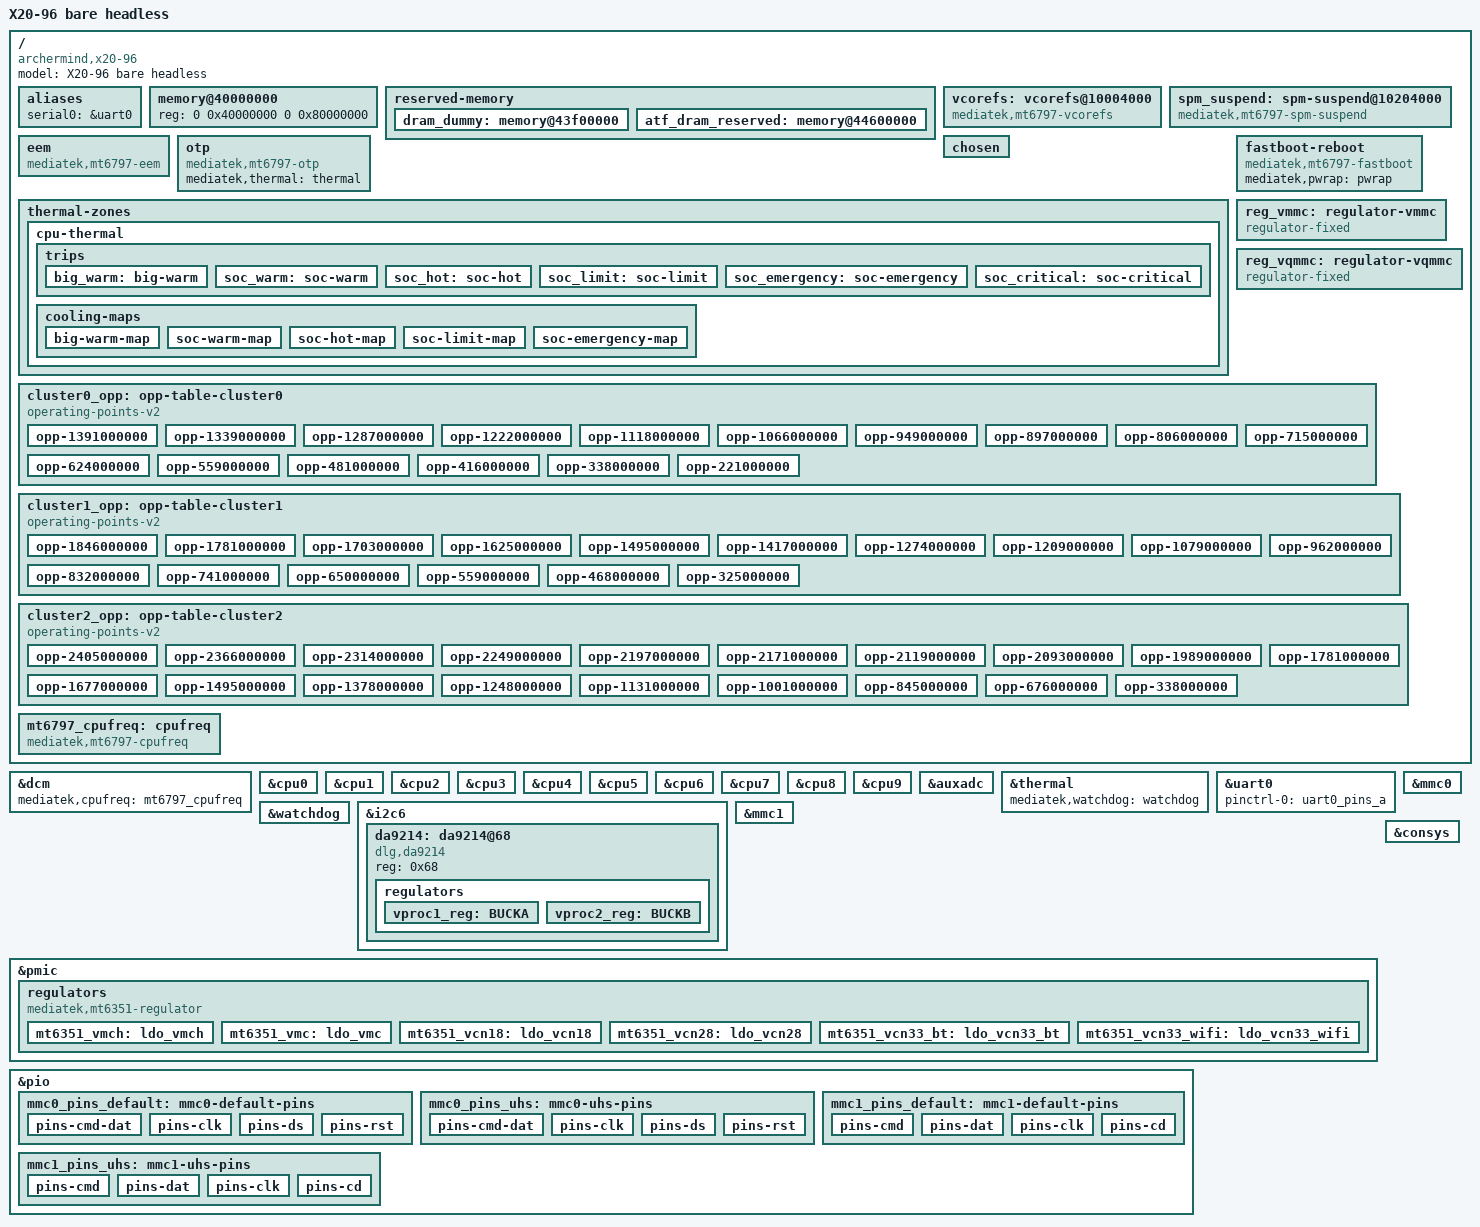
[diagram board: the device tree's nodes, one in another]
// SPDX-License-Identifier: GPL-2.0-only
/*
 * Device Tree for the bare X20-96 board.
 *
 * This is intentionally the first, headless bring-up description.  The board
 * has no display or expansion board attached, so only the serial console is
 * enabled until each onboard peripheral is verified separately.
 */

/dts-v1/;

#include <dt-bindings/pinctrl/mt65xx.h>
#include <dt-bindings/gpio/gpio.h>
#include <dt-bindings/regulator/dlg,da9211-regulator.h>
#include <dt-bindings/thermal/thermal.h>
#include "mt6797-x20-96-cooling.h"
#include "mt6797.dtsi"

&dcm {
	mediatek,cpufreq = <&mt6797_cpufreq>;
	status = "okay";
};

/ {
	model = "X20-96 bare headless";
	compatible = "archermind,x20-96", "mediatek,mt6797";

	aliases {
		serial0 = &uart0;
	};

	memory@40000000 {
		device_type = "memory";
		reg = <0 0x40000000 0 0x80000000>;
	};

	reserved-memory {
		#address-cells = <2>;
		#size-cells = <2>;
		ranges;

		/* Dedicated dummy reads for the board's single DRAM rank. */
		dram_dummy: memory@43f00000 {
			reg = <0 0x43f00000 0 0x1000>;
			no-map;
		};

		/* The BSP Preloader locks this former BL31 DRAM window in EMI MPU. */
		atf_dram_reserved: memory@44600000 {
			reg = <0 0x44600000 0 0x10000>;
			no-map;
		};
	};

	vcorefs: vcorefs@10004000 {
		compatible = "mediatek,mt6797-vcorefs";
		reg = <0 0x10004000 0 0x1000>,
		      <0 0x1000f000 0 0x1000>,
		      <0 0x1000d10c 0 0x80>,
		      <0 0x08000008 0 4>,
		      <0 0x11015000 0 0x1000>,
		      <0 0x11016000 0 0x1000>;
		reg-names = "dramc", "ddrphy", "pwrap-dvfs", "chip-version",
			    "cpu-spm", "big-spm";
		mediatek,infracfg = <&infrasys>;
		mediatek,spm = <&scpsys>;
		mediatek,pmic-wrapper = <&pwrap>;
		mediatek,dcm = <&dcm>;
		clocks = <&topckgen CLK_TOP_MUX_SPM>,
			 <&infrasys CLK_INFRA_DVFS_SPM1>,
			 <&topckgen CLK_TOP_MUX_DDRPHYCFG>,
			 <&infrasys CLK_INFRA_DRAMC_CONF>,
			 <&infrasys CLK_INFRA_DRAMC_B_CONF>,
			 <&topckgen CLK_TOP_MUX_AXI>,
			 <&topckgen CLK_TOP_SYSPLL_D7>,
			 <&topckgen CLK_TOP_MUX_ULPOSC_AXI_CK_MUX>;
		clock-names = "spm", "dvfs", "ddrphy", "dramc", "dramc-b",
			      "axi", "axi-high", "axi-low";
		memory-region = <&dram_dummy>;
	};

	spm_suspend: spm-suspend@10204000 {
		compatible = "mediatek,mt6797-spm-suspend";
		reg = <0 0x10204000 0 0x1000>;
		clocks = <&infrasys CLK_INFRA_SYS_CIRQ>;
		clock-names = "cirq";
		mediatek,vcorefs = <&vcorefs>;
		mediatek,watchdog = <&watchdog>;
		mediatek,gic = <&gic>;
		mediatek,sysirq = <&sysirq>;
		interrupt-parent = <&sysirq>;
		interrupts = <GIC_SPI 180 IRQ_TYPE_LEVEL_LOW>;
		wakeup-source;
	};

	eem {
		compatible = "mediatek,mt6797-eem";
		mediatek,thermal = <&thermal>;
		mediatek,cpufreq = <&mt6797_cpufreq>;
		nvmem-cells = <&eem_calibration>;
		nvmem-cell-names = "calibration-data";
	};

	otp {
		compatible = "mediatek,mt6797-otp";
		mediatek,thermal = <&thermal>;
	};

	chosen {
		stdout-path = "serial0:921600n8";
		/* Loader overrides this for initramfs rescue; fallback is eMMC. */
		bootargs = "console=ttyS0,921600n8 root=PARTUUID=8273e1ab-846f-4468-b999-ee2ea8e50a16 rootwait printk.time=1";
	};

	thermal-zones {
		cpu-thermal {
			polling-delay-passive = <100>;
			polling-delay = <100>;
			thermal-sensors = <&thermal>;

			trips {
				big_warm: big-warm {
					temperature = <120000>;
					hysteresis = <5000>;
					type = "passive";
				};

				soc_warm: soc-warm {
					temperature = <135000>;
					hysteresis = <10000>;
					type = "passive";
				};

				soc_hot: soc-hot {
					temperature = <140000>;
					hysteresis = <10000>;
					type = "passive";
				};

				soc_limit: soc-limit {
					temperature = <143000>;
					hysteresis = <13000>;
					type = "passive";
				};

				soc_emergency: soc-emergency {
					temperature = <145000>;
					hysteresis = <15000>;
					type = "passive";
				};

				soc_critical: soc-critical {
					temperature = <150000>;
					hysteresis = <2000>;
					type = "critical";
				};
			};

			cooling-maps {
				big-warm-map {
					trip = <&big_warm>;
					cooling-device = <&cpu8 X20_BIG_STATE_2314000
							 X20_BIG_STATE_2314000>;
				};

				soc-warm-map {
					trip = <&soc_warm>;
					cooling-device = <&cpu8 X20_BIG_STATE_1677000
							 X20_BIG_STATE_1677000>,
							 <&cpu0 X20_LL_STATE_1066000
							 X20_LL_STATE_1066000>,
							 <&cpu4 X20_L_STATE_1209000
							 X20_L_STATE_1209000>;
				};

				soc-hot-map {
					trip = <&soc_hot>;
					cooling-device = <&cpu8 X20_BIG_STATE_1495000
							 X20_BIG_STATE_1495000>,
							 <&cpu0 X20_LL_STATE_806000
							 X20_LL_STATE_806000>,
							 <&cpu4 X20_L_STATE_832000
							 X20_L_STATE_832000>;
				};

				soc-limit-map {
					trip = <&soc_limit>;
					cooling-device = <&cpu8 X20_BIG_STATE_1001000
							 X20_BIG_STATE_1001000>,
							 <&cpu0 X20_LL_STATE_559000
							 X20_LL_STATE_559000>,
							 <&cpu4 X20_L_STATE_650000
							 X20_L_STATE_650000>;
				};

				soc-emergency-map {
					trip = <&soc_emergency>;
					cooling-device = <&cpu8 X20_BIG_STATE_338000
							 X20_BIG_STATE_338000>,
							 <&cpu0 X20_LL_STATE_221000
							 X20_LL_STATE_221000>,
							 <&cpu4 X20_L_STATE_325000
							 X20_L_STATE_325000>;
				};
			};
		};
	};

	fastboot-reboot {
		compatible = "mediatek,mt6797-fastboot";
		mediatek,pwrap = <&pwrap>;
	};

	reg_vmmc: regulator-vmmc {
		compatible = "regulator-fixed";
		regulator-name = "vmmc-3v3";
		regulator-min-microvolt = <3300000>;
		regulator-max-microvolt = <3300000>;
		regulator-always-on;
		regulator-boot-on;
	};

	reg_vqmmc: regulator-vqmmc {
		compatible = "regulator-fixed";
		regulator-name = "vqmmc-1v8";
		regulator-min-microvolt = <1800000>;
		regulator-max-microvolt = <1800000>;
		regulator-always-on;
		regulator-boot-on;
	};

	/* FY operating points copied from the vendor MT6797 tables. */
	cluster0_opp: opp-table-cluster0 {
		compatible = "operating-points-v2";
		opp-shared;
		clock-latency-ns = <30000>;

		opp-1391000000 { opp-hz = /bits/ 64 <1391000000>; opp-microvolt = <1180000>; };
		opp-1339000000 { opp-hz = /bits/ 64 <1339000000>; opp-microvolt = <1160000>; };
		opp-1287000000 { opp-hz = /bits/ 64 <1287000000>; opp-microvolt = <1130000>; };
		opp-1222000000 { opp-hz = /bits/ 64 <1222000000>; opp-microvolt = <1110000>; };
		opp-1118000000 { opp-hz = /bits/ 64 <1118000000>; opp-microvolt = <1090000>; };
		opp-1066000000 { opp-hz = /bits/ 64 <1066000000>; opp-microvolt = <1070000>; };
		opp-949000000 { opp-hz = /bits/ 64 <949000000>; opp-microvolt = <1020000>; };
		opp-897000000 { opp-hz = /bits/ 64 <897000000>; opp-microvolt = <1000000>; };
		opp-806000000 { opp-hz = /bits/ 64 <806000000>; opp-microvolt = <970000>; };
		opp-715000000 { opp-hz = /bits/ 64 <715000000>; opp-microvolt = <940000>; };
		opp-624000000 { opp-hz = /bits/ 64 <624000000>; opp-microvolt = <900000>; };
		opp-559000000 { opp-hz = /bits/ 64 <559000000>; opp-microvolt = <880000>; };
		opp-481000000 { opp-hz = /bits/ 64 <481000000>; opp-microvolt = <850000>; };
		opp-416000000 { opp-hz = /bits/ 64 <416000000>; opp-microvolt = <830000>; };
		opp-338000000 { opp-hz = /bits/ 64 <338000000>; opp-microvolt = <800000>; };
		opp-221000000 { opp-hz = /bits/ 64 <221000000>; opp-microvolt = <780000>; };
	};

	cluster1_opp: opp-table-cluster1 {
		compatible = "operating-points-v2";
		opp-shared;
		clock-latency-ns = <30000>;

		opp-1846000000 { opp-hz = /bits/ 64 <1846000000>; opp-microvolt = <1180000>; };
		opp-1781000000 { opp-hz = /bits/ 64 <1781000000>; opp-microvolt = <1160000>; };
		opp-1703000000 { opp-hz = /bits/ 64 <1703000000>; opp-microvolt = <1130000>; };
		opp-1625000000 { opp-hz = /bits/ 64 <1625000000>; opp-microvolt = <1110000>; };
		opp-1495000000 { opp-hz = /bits/ 64 <1495000000>; opp-microvolt = <1090000>; };
		opp-1417000000 { opp-hz = /bits/ 64 <1417000000>; opp-microvolt = <1070000>; };
		opp-1274000000 { opp-hz = /bits/ 64 <1274000000>; opp-microvolt = <1020000>; };
		opp-1209000000 { opp-hz = /bits/ 64 <1209000000>; opp-microvolt = <1000000>; };
		opp-1079000000 { opp-hz = /bits/ 64 <1079000000>; opp-microvolt = <970000>; };
		opp-962000000 { opp-hz = /bits/ 64 <962000000>; opp-microvolt = <940000>; };
		opp-832000000 { opp-hz = /bits/ 64 <832000000>; opp-microvolt = <900000>; };
		opp-741000000 { opp-hz = /bits/ 64 <741000000>; opp-microvolt = <880000>; };
		opp-650000000 { opp-hz = /bits/ 64 <650000000>; opp-microvolt = <850000>; };
		opp-559000000 { opp-hz = /bits/ 64 <559000000>; opp-microvolt = <830000>; };
		opp-468000000 { opp-hz = /bits/ 64 <468000000>; opp-microvolt = <800000>; };
		opp-325000000 { opp-hz = /bits/ 64 <325000000>; opp-microvolt = <780000>; };
	};

	cluster2_opp: opp-table-cluster2 {
		compatible = "operating-points-v2";
		opp-shared;
		clock-latency-ns = <30000>;

		/* Board experiment curve; no requests above the verified 2.405 GHz. */
		/* Highest tested execution point, using the user voltage curve. */
		opp-2405000000 { opp-hz = /bits/ 64 <2405000000>; opp-microvolt = <1110000>; };
		opp-2366000000 { opp-hz = /bits/ 64 <2366000000>; opp-microvolt = <1090000>; };
		opp-2314000000 { opp-hz = /bits/ 64 <2314000000>; opp-microvolt = <1070000>; };
		opp-2249000000 { opp-hz = /bits/ 64 <2249000000>; opp-microvolt = <1160000>; };
		opp-2197000000 { opp-hz = /bits/ 64 <2197000000>; opp-microvolt = <1150000>; };
		opp-2171000000 { opp-hz = /bits/ 64 <2171000000>; opp-microvolt = <1140000>; };
		opp-2119000000 { opp-hz = /bits/ 64 <2119000000>; opp-microvolt = <1120000>; };
		opp-2093000000 { opp-hz = /bits/ 64 <2093000000>; opp-microvolt = <1110000>; };
		opp-1989000000 { opp-hz = /bits/ 64 <1989000000>; opp-microvolt = <1100000>; };
		opp-1781000000 { opp-hz = /bits/ 64 <1781000000>; opp-microvolt = <1060000>; };
		opp-1677000000 { opp-hz = /bits/ 64 <1677000000>; opp-microvolt = <1040000>; };
		opp-1495000000 { opp-hz = /bits/ 64 <1495000000>; opp-microvolt = <990000>; };
		opp-1378000000 { opp-hz = /bits/ 64 <1378000000>; opp-microvolt = <970000>; };
		opp-1248000000 { opp-hz = /bits/ 64 <1248000000>; opp-microvolt = <940000>; };
		opp-1131000000 { opp-hz = /bits/ 64 <1131000000>; opp-microvolt = <920000>; };
		opp-1001000000 { opp-hz = /bits/ 64 <1001000000>; opp-microvolt = <890000>; };
		opp-845000000 { opp-hz = /bits/ 64 <845000000>; opp-microvolt = <870000>; };
		opp-676000000 { opp-hz = /bits/ 64 <676000000>; opp-microvolt = <840000>; };
		opp-338000000 { opp-hz = /bits/ 64 <338000000>; opp-microvolt = <800000>; };
	};

	mt6797_cpufreq: cpufreq {
		compatible = "mediatek,mt6797-cpufreq";
		reg = <0 0x1001a000 0 0x1000>,
		      <0 0x10000000 0 0x1000>,
		      <0 0x11015000 0 0x1000>,
		      <0 0x10001000 0 0x1000>;
		reg-names = "mcumixed", "topckgen", "semaphore", "infracfg";
		status = "okay";
	};
};

/* Short on-board Dhrystone gives A53:A72 DMIPS/MHz approximately 2:3.
 * Linux combines these per-MHz weights with each policy maximum.
 */
&cpu0 { operating-points-v2 = <&cluster0_opp>; capacity-dmips-mhz = <667>; cpu-supply = <&vproc1_reg>; };
&cpu1 { operating-points-v2 = <&cluster0_opp>; capacity-dmips-mhz = <667>; cpu-supply = <&vproc1_reg>; };
&cpu2 { operating-points-v2 = <&cluster0_opp>; capacity-dmips-mhz = <667>; cpu-supply = <&vproc1_reg>; };
&cpu3 { operating-points-v2 = <&cluster0_opp>; capacity-dmips-mhz = <667>; cpu-supply = <&vproc1_reg>; };
&cpu4 { operating-points-v2 = <&cluster1_opp>; capacity-dmips-mhz = <667>; cpu-supply = <&vproc1_reg>; };
&cpu5 { operating-points-v2 = <&cluster1_opp>; capacity-dmips-mhz = <667>; cpu-supply = <&vproc1_reg>; };
&cpu6 { operating-points-v2 = <&cluster1_opp>; capacity-dmips-mhz = <667>; cpu-supply = <&vproc1_reg>; };
&cpu7 { operating-points-v2 = <&cluster1_opp>; capacity-dmips-mhz = <667>; cpu-supply = <&vproc1_reg>; };
&cpu8 { operating-points-v2 = <&cluster2_opp>; capacity-dmips-mhz = <1000>; cpu-supply = <&vproc2_reg>; };
&cpu9 { operating-points-v2 = <&cluster2_opp>; capacity-dmips-mhz = <1000>; cpu-supply = <&vproc2_reg>; };

&auxadc {
	status = "okay";
};

&thermal {
	mediatek,watchdog = <&watchdog>;
	status = "okay";
};

&uart0 {
	status = "okay";
	pinctrl-names = "default";
	pinctrl-0 = <&uart0_pins_a>;
};

/* TOPRGU is the board's hardware reset path, including reboot-to-Fastboot. */
&watchdog {
	status = "okay";
};

/* The board carries the vendor-designated DA9214 VPROC buck at I2C6/0x68. */
&i2c6 {
	pinctrl-names = "default";
	pinctrl-0 = <&i2c6_pins_a>;
	clock-frequency = <3400000>;
	mediatek,use-push-pull;
	status = "okay";

	da9214: da9214@68 {
		compatible = "dlg,da9214";
		reg = <0x68>;

		regulators {
			vproc1_reg: BUCKA {
				regulator-name = "vproc1";
				regulator-min-microvolt = <780000>;
				regulator-max-microvolt = <1200000>;
				regulator-initial-mode = <DA9211_BUCK_MODE_SYNC>;
				regulator-allowed-modes = <DA9211_BUCK_MODE_SYNC
						   DA9211_BUCK_MODE_AUTO>;
				regulator-always-on;
			};

			vproc2_reg: BUCKB {
				regulator-name = "vproc2";
				regulator-min-microvolt = <800000>;
				regulator-max-microvolt = <1200000>;
				regulator-initial-mode = <DA9211_BUCK_MODE_SYNC>;
				regulator-allowed-modes = <DA9211_BUCK_MODE_SYNC
						   DA9211_BUCK_MODE_AUTO>;
				regulator-always-on;
			};
		};
	};
};

&mmc0 {
	/* Validated high-throughput descriptor DMA path for HS400. */
	bus-width = <8>;
	max-frequency = <200000000>;
	cap-mmc-highspeed;
	mmc-ddr-1_8v;
	mmc-hs200-1_8v;
	mmc-hs400-1_8v;
	mediatek,latch-ck = <1>;
	mediatek,tuning-step = <64>;
	non-removable;
	no-sd;
	no-sdio;
	vmmc-supply = <&reg_vmmc>;
	vqmmc-supply = <&reg_vqmmc>;
	pinctrl-names = "default", "state_uhs";
	pinctrl-0 = <&mmc0_pins_default>;
	pinctrl-1 = <&mmc0_pins_uhs>;
	status = "okay";
};

&mmc1 {
	/* Validated UHS-I path; the Loader still boots eMMC/MSDC0 only. */
	bus-width = <4>;
	max-frequency = <104000000>;
	cap-sd-highspeed;
	sd-uhs-sdr104;
	/* This X20-96 board reports card insertion high on GPIO67. */
	cd-gpios = <&pio 67 GPIO_ACTIVE_HIGH>;
	vmmc-supply = <&mt6351_vmch>;
	vqmmc-supply = <&mt6351_vmc>;
	pinctrl-names = "default", "state_uhs";
	pinctrl-0 = <&mmc1_pins_default>;
	pinctrl-1 = <&mmc1_pins_uhs>;
	status = "okay";
};

&pmic {
	regulators {
		compatible = "mediatek,mt6351-regulator";

		mt6351_vmch: ldo_vmch {
			regulator-name = "vmch";
			regulator-min-microvolt = <3300000>;
			regulator-max-microvolt = <3300000>;
			regulator-always-on;
			regulator-boot-on;
		};

		mt6351_vmc: ldo_vmc {
			regulator-name = "vmc";
			regulator-min-microvolt = <1800000>;
			/* SD legacy/high-speed signalling starts at 3.3 V. */
			regulator-max-microvolt = <3300000>;
			regulator-boot-on;
		};

		/*
		 * Connectivity rails for the MT6797 ConSys and the MT6631
		 * radio: AVDD18_WBT, TCXO/FM 2.8 V and the separate VCN33
		 * BT/WiFi outputs.  Each rail has a hardware-fixed voltage.
		 */
		mt6351_vcn18: ldo_vcn18 {
			regulator-name = "vcn18";
			regulator-min-microvolt = <1800000>;
			regulator-max-microvolt = <1800000>;
		};

		mt6351_vcn28: ldo_vcn28 {
			regulator-name = "vcn28";
			regulator-min-microvolt = <2800000>;
			regulator-max-microvolt = <2800000>;
		};

		mt6351_vcn33_bt: ldo_vcn33_bt {
			regulator-name = "vcn33_bt";
			regulator-min-microvolt = <3300000>;
			regulator-max-microvolt = <3300000>;
		};

		mt6351_vcn33_wifi: ldo_vcn33_wifi {
			regulator-name = "vcn33_wifi";
			regulator-min-microvolt = <3300000>;
			regulator-max-microvolt = <3300000>;
		};
	};
};

/* Wi-Fi/BT/GPS connectivity subsystem; driver is an opt-in module. */
&consys {
	status = "okay";
};

&pio {
	mmc0_pins_default: mmc0-default-pins {
		pins-cmd-dat {
			pinmux = <MT6797_GPIO114__FUNC_MSDC0_DAT0>,
				 <MT6797_GPIO115__FUNC_MSDC0_DAT1>,
				 <MT6797_GPIO116__FUNC_MSDC0_DAT2>,
				 <MT6797_GPIO117__FUNC_MSDC0_DAT3>,
				 <MT6797_GPIO118__FUNC_MSDC0_DAT4>,
				 <MT6797_GPIO119__FUNC_MSDC0_DAT5>,
				 <MT6797_GPIO120__FUNC_MSDC0_DAT6>,
				 <MT6797_GPIO121__FUNC_MSDC0_DAT7>,
				 <MT6797_GPIO122__FUNC_MSDC0_CMD>;
			input-enable;
			input-schmitt-enable;
			bias-pull-up = <MTK_PUPD_SET_R1R0_01>;
			drive-strength = <4>;
			mediatek,tdsel = <0>;
			mediatek,rdsel = <0>;
		};

		pins-clk {
			pinmux = <MT6797_GPIO123__FUNC_MSDC0_CLK>;
			input-enable;
			input-schmitt-enable;
			bias-pull-down = <MTK_PUPD_SET_R1R0_10>;
			drive-strength = <4>;
			mediatek,tdsel = <0>;
			mediatek,rdsel = <0>;
		};

		pins-ds {
			pinmux = <MT6797_GPIO124__FUNC_MSDC0_DSL>;
			input-enable;
			input-schmitt-enable;
			bias-pull-down = <MTK_PUPD_SET_R1R0_10>;
			drive-strength = <4>;
			mediatek,tdsel = <0>;
			mediatek,rdsel = <0>;
		};

		pins-rst {
			pinmux = <MT6797_GPIO125__FUNC_MSDC0_RSTB>;
			input-enable;
			input-schmitt-enable;
			bias-pull-up = <MTK_PUPD_SET_R1R0_01>;
			drive-strength = <4>;
			mediatek,tdsel = <0>;
			mediatek,rdsel = <0>;
		};
	};

	mmc0_pins_uhs: mmc0-uhs-pins {
		pins-cmd-dat {
			pinmux = <MT6797_GPIO114__FUNC_MSDC0_DAT0>,
				 <MT6797_GPIO115__FUNC_MSDC0_DAT1>,
				 <MT6797_GPIO116__FUNC_MSDC0_DAT2>,
				 <MT6797_GPIO117__FUNC_MSDC0_DAT3>,
				 <MT6797_GPIO118__FUNC_MSDC0_DAT4>,
				 <MT6797_GPIO119__FUNC_MSDC0_DAT5>,
				 <MT6797_GPIO120__FUNC_MSDC0_DAT6>,
				 <MT6797_GPIO121__FUNC_MSDC0_DAT7>,
				 <MT6797_GPIO122__FUNC_MSDC0_CMD>;
			input-enable;
			input-schmitt-enable;
			bias-pull-up = <MTK_PUPD_SET_R1R0_01>;
			drive-strength = <4>;
			mediatek,tdsel = <0>;
			mediatek,rdsel = <0>;
		};

		pins-clk {
			pinmux = <MT6797_GPIO123__FUNC_MSDC0_CLK>;
			input-enable;
			input-schmitt-enable;
			bias-pull-down = <MTK_PUPD_SET_R1R0_10>;
			drive-strength = <4>;
			mediatek,tdsel = <0>;
			mediatek,rdsel = <0>;
		};

		pins-ds {
			pinmux = <MT6797_GPIO124__FUNC_MSDC0_DSL>;
			input-enable;
			input-schmitt-enable;
			bias-pull-down = <MTK_PUPD_SET_R1R0_10>;
			drive-strength = <4>;
			mediatek,tdsel = <0>;
			mediatek,rdsel = <0>;
		};

		pins-rst {
			pinmux = <MT6797_GPIO125__FUNC_MSDC0_RSTB>;
			input-enable;
			input-schmitt-enable;
			bias-pull-up = <MTK_PUPD_SET_R1R0_01>;
			drive-strength = <4>;
			mediatek,tdsel = <0>;
			mediatek,rdsel = <0>;
		};
	};

	mmc1_pins_default: mmc1-default-pins {
		pins-cmd {
			pinmux = <MT6797_GPIO129__FUNC_MSDC1_CMD>;
			input-enable;
			input-schmitt-enable;
			bias-pull-up = <MTK_PUPD_SET_R1R0_10>;
			drive-strength = <4>;
			mediatek,tdsel = <10>;
			mediatek,rdsel = <3>;
		};

		pins-dat {
			pinmux = <MT6797_GPIO130__FUNC_MSDC1_DAT0>,
				 <MT6797_GPIO131__FUNC_MSDC1_DAT1>,
				 <MT6797_GPIO132__FUNC_MSDC1_DAT2>,
				 <MT6797_GPIO133__FUNC_MSDC1_DAT3>;
			input-enable;
			input-schmitt-enable;
			bias-pull-up = <MTK_PUPD_SET_R1R0_10>;
			drive-strength = <4>;
			mediatek,tdsel = <10>;
			mediatek,rdsel = <3>;
		};

		pins-clk {
			pinmux = <MT6797_GPIO134__FUNC_MSDC1_CLK>;
			input-enable;
			input-schmitt-enable;
			bias-pull-down = <MTK_PUPD_SET_R1R0_10>;
			drive-strength = <4>;
			mediatek,tdsel = <10>;
			mediatek,rdsel = <0>;
		};

		pins-cd {
			pinmux = <MT6797_GPIO67__FUNC_GPIO67>;
			input-enable;
			bias-pull-up;
		};
	};

	mmc1_pins_uhs: mmc1-uhs-pins {
		pins-cmd {
			pinmux = <MT6797_GPIO129__FUNC_MSDC1_CMD>;
			input-enable;
			input-schmitt-enable;
			bias-pull-up = <MTK_PUPD_SET_R1R0_10>;
			drive-strength = <4>;
			mediatek,tdsel = <10>;
			mediatek,rdsel = <0>;
		};

		pins-dat {
			pinmux = <MT6797_GPIO130__FUNC_MSDC1_DAT0>,
				 <MT6797_GPIO131__FUNC_MSDC1_DAT1>,
				 <MT6797_GPIO132__FUNC_MSDC1_DAT2>,
				 <MT6797_GPIO133__FUNC_MSDC1_DAT3>;
			input-enable;
			input-schmitt-enable;
			bias-pull-up = <MTK_PUPD_SET_R1R0_10>;
			drive-strength = <4>;
			mediatek,tdsel = <10>;
			mediatek,rdsel = <0>;
		};

		pins-clk {
			pinmux = <MT6797_GPIO134__FUNC_MSDC1_CLK>;
			input-enable;
			input-schmitt-enable;
			bias-pull-down = <MTK_PUPD_SET_R1R0_10>;
			drive-strength = <4>;
			mediatek,tdsel = <10>;
			mediatek,rdsel = <0>;
		};

		pins-cd {
			pinmux = <MT6797_GPIO67__FUNC_GPIO67>;
			input-enable;
			bias-pull-up;
		};
	};
};
